# PIC18F16Q41 register map
Vendor: Microchip
Registers are 8-bit, read-write, reset 0x0 unless marked. A register's access mark holds for its fields unless they carry their own. Addresses are absolute, and some are shared; only a register's first bit layout is shown; [hi:lo] are bit positions; {n}, {i} and the like mark numbered series.

## wg_ecwg
0x3BC CWG1CLK
  [0] CS
0x3BD CWG1ISM
  [3:0] ISM
0x3BE CWG1DBR
  [5:0] DBR
0x3BF CWG1DBF
  [5:0] DBF
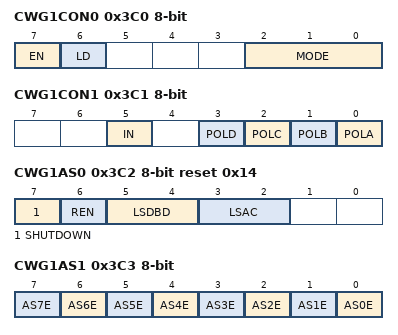
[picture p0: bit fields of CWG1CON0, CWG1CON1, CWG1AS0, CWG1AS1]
0x3C0 CWG1CON0
  [7] EN, [6] LD, [2:0] MODE
0x3C1 CWG1CON1 reset not defined — (power-on value --x-0000)
  [5] IN ro, [3] POLD, [2] POLC, [1] POLB, [0] POLA
0x3C2 CWG1AS0 reset 0x14
  [7] SHUTDOWN, [6] REN, [5:4] LSDBD, [3:2] LSAC
0x3C3 CWG1AS1
  [n] AS{n}E (n=0..7)
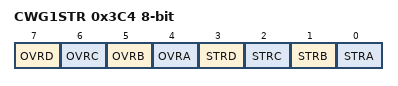
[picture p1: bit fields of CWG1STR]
0x3C4 CWG1STR
  [7] OVRD, [6] OVRC, [5] OVRB, [4] OVRA, [3] STRD, [2] STRC, [1] STRB, [0] STRA

## amp_fvr_ts_ctrl
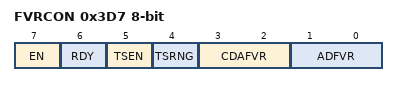
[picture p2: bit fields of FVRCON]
0x3D7 FVRCON reset not defined — (power-on value xx000000)
  [7] EN — Zero-Cross Detect Software Enable bit
  [6] RDY ro
  [5] TSEN — Zero-Cross Detect Data Output
  [4] TSRNG — Zero-Cross Detect Polarity bit
  [3:2] CDAFVR
  [1:0] ADFVR — Zero-Cross Detect Positive-going Edge Interrupt Enable

## adc_sarcore_mp_ctrl
0x3D9 ADLTHL
  [7:0] LTH
0x3DA ADLTHH
  [7:0] LTH
0x3DB ADUTHL
  [7:0] UTH
0x3DC ADUTHH
  [7:0] UTH
0x3DD ADERRL ro reset not defined — (power-on value xxxxxxxx)
  [7:0] ERR
0x3DE ADERRH ro reset not defined — (power-on value xxxxxxxx)
  [7:0] ERR
0x3DF ADSTPTL
  [7:0] STPT
0x3E0 ADSTPTH
  [7:0] STPT
0x3E1 ADFLTRL ro reset not defined — (power-on value xxxxxxxx)
  [7:0] FLTR
0x3E2 ADFLTRH ro reset not defined — (power-on value xxxxxxxx)
  [7:0] FLTR
0x3E3 ADACCL reset not defined — (power-on value xxxxxxxx)
  [7:0] ACC
0x3E4 ADACCH reset not defined — (power-on value xxxxxxxx)
  [7:0] ACC
0x3E5 ADACCU reset not defined — (power-on value xxxxxxxx)
  [7:0] ACC
0x3E6 ADCNT reset not defined — (power-on value xxxxxxxx)
  [7:0] CNT
0x3E7 ADRPT
  [7:0] RPT
0x3E8 ADPREVL ro reset not defined — (power-on value xxxxxxxx)
  [7:0] PREV
0x3E9 ADPREVH ro reset not defined — (power-on value xxxxxxxx)
  [7:0] PREV
0x3EA ADRESL
  [7:0] RES
0x3EB ADRESH
  [7:0] RES
0x3EC ADPCH
  [7:0] PCH
0x3EE ADACQL
  [7:0] ACQ
0x3EF ADACQH
  [4:0] ACQ
0x3F0 ADCAP
  [4:0] CAP
0x3F1 ADPREL
  [7:0] PRE
0x3F2 ADPREH
  [4:0] PRE
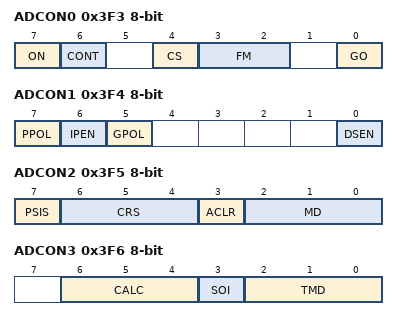
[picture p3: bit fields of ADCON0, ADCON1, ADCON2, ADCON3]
0x3F3 ADCON0
  [7] ON, [6] CONT, [4] CS, [3:2] FM, [0] GO
0x3F4 ADCON1
  [7] PPOL, [6] IPEN, [5] GPOL, [0] DSEN
0x3F5 ADCON2
  [7] PSIS, [6:4] CRS, [3] ACLR, [2:0] MD
0x3F6 ADCON3
  [6:4] CALC, [3] SOI, [2:0] TMD
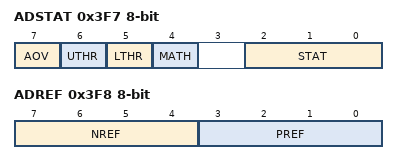
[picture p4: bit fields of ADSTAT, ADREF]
0x3F7 ADSTAT
  [7] AOV ro
  [6] UTHR ro
  [5] LTHR ro
  [4] MATH — (can only be cleared)
  [2:0] STAT ro
0x3F8 ADREF
  [7:4] NREF, [3:0] PREF
0x3F9 ADACT
  [4:0] ACT
0x3FA ADCLK
  [5:0] CS

## DOS_xxxxx_port_control
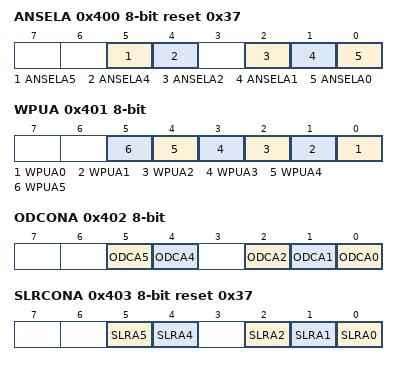
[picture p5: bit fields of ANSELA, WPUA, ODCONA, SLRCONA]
0x400 ANSELA reset 0x37
  [5] ANSELA5, [4] ANSELA4, [2] ANSELA2, [1] ANSELA1, [0] ANSELA0
0x401 WPUA
  [n] WPUA{n} (n=0..5)
0x402 ODCONA
  [5] ODCA5, [4] ODCA4, [2] ODCA2, [1] ODCA1, [0] ODCA0
0x403 SLRCONA reset 0x37
  [5] SLRA5, [4] SLRA4, [2] SLRA2, [1] SLRA1, [0] SLRA0
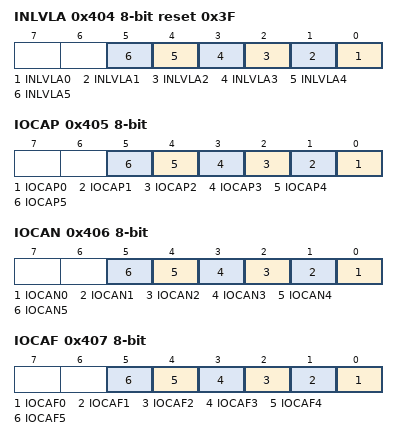
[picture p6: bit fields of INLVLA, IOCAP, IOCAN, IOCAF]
0x404 INLVLA reset 0x3F
  [n] INLVLA{n} (n=0..5)
0x405 IOCAP
  [n] IOCAP{n} (n=0..5)
0x406 IOCAN
  [n] IOCAN{n} (n=0..5)
0x407 IOCAF
  [n] IOCAF{n} (n=0..5)
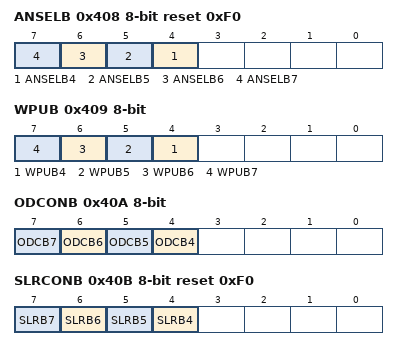
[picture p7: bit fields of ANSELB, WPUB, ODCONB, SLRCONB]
0x408 ANSELB reset 0xF0
  [n] ANSELB{n} (n=4..7)
0x409 WPUB
  [n] WPUB{n} (n=4..7)
0x40A ODCONB
  [n] ODCB{n} (n=4..7)
0x40B SLRCONB reset 0xF0
  [n] SLRB{n} (n=4..7)
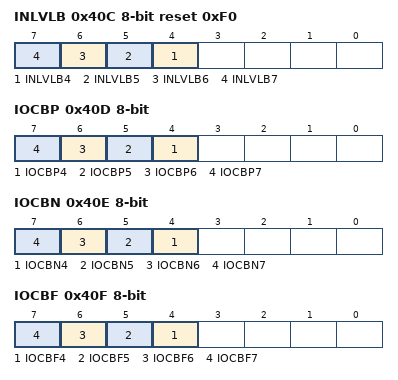
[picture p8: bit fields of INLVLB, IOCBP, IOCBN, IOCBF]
0x40C INLVLB reset 0xF0
  [n] INLVLB{n} (n=4..7)
0x40D IOCBP
  [n] IOCBP{n} (n=4..7)
0x40E IOCBN
  [n] IOCBN{n} (n=4..7)
0x40F IOCBF
  [n] IOCBF{n} (n=4..7)
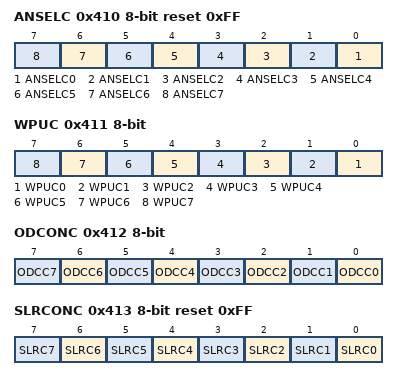
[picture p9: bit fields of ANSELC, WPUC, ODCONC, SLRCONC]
0x410 ANSELC reset 0xFF
  [n] ANSELC{n} (n=0..7)
0x411 WPUC
  [n] WPUC{n} (n=0..7)
0x412 ODCONC
  [n] ODCC{n} (n=0..7)
0x413 SLRCONC reset 0xFF
  [n] SLRC{n} (n=0..7)
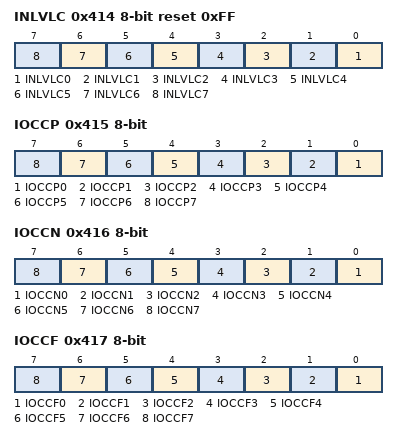
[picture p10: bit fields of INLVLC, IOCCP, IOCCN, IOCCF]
0x414 INLVLC reset 0xFF
  [n] INLVLC{n} (n=0..7)
0x415 IOCCP
  [n] IOCCP{n} (n=0..7)
0x416 IOCCN
  [n] IOCCN{n} (n=0..7)
0x417 IOCCF
  [n] IOCCF{n} (n=0..7)

## tmr_dds
0x440 NCO1ACCL
  [7:0] ACC
0x441 NCO1ACCH
  [7:0] ACC
0x442 NCO1ACCU
  [3:0] ACC
0x443 NCO1INCL reset 0x1
  [7:0] INC
0x444 NCO1INCH
  [7:0] INC
0x445 NCO1INCU
  [3:0] INC
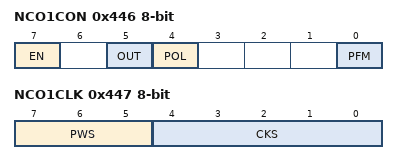
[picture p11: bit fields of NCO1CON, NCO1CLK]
0x446 NCO1CON — Configurable logic cell control
  [7] EN, [5] OUT ro, [4] POL, [0] PFM
0x447 NCO1CLK
  [7:5] PWS, [4:0] CKS

## int
0x459 IVTLOCK
  [0] IVTLOCKED
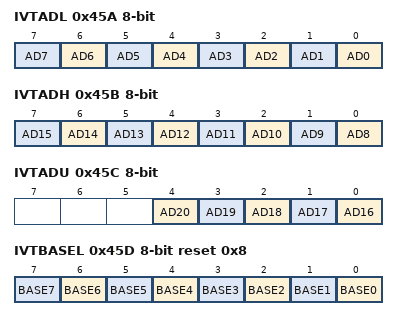
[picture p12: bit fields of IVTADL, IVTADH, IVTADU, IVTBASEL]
0x45A IVTADL
  [n] AD{n} (n=0..7)
0x45B IVTADH
  [n-8] AD{n} (n=8..15)
0x45C IVTADU
  [n-16] AD{n} (n=16..20)
0x45D IVTBASEL reset 0x8
  [n] BASE{n} (n=0..7)
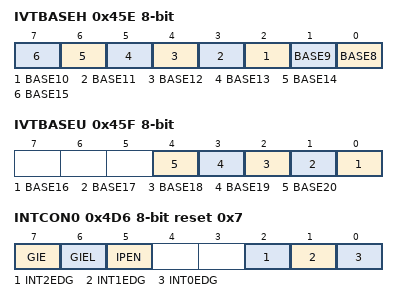
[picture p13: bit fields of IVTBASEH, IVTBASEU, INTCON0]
0x45E IVTBASEH
  [n-8] BASE{n} (n=8..15)
0x45F IVTBASEU
  [n-16] BASE{n} (n=16..20)
0x4D6 INTCON0 reset 0x7
  [7] GIE, [6] GIEL, [5] IPEN, [2] INT2EDG, [1] INT1EDG, [0] INT0EDG
0x4D7 INTCON1 ro
  [7:6] STAT

## pwm_cmp
{0x451+0xF*i} PWM{i}ERS (i=1..3)
  [7:0] ERS
{0x452+0xF*i} PWM{i}CLK (i=1..3)
  [7:0] CLK
{0x453+0xF*i} PWM{i}LDS (i=1..3)
  [7:0] LDS
{0x454+0xF*i} PWM{i}PRL (i=1..3)
  [7:0] PRL
{0x455+0xF*i} PWM{i}PRH (i=1..3)
  [7:0] PRH
{0x456+0xF*i} PWM{i}CPRE (i=1..3)
  [7:0] CPRE
{0x457+0xF*i} PWM{i}PIPOS (i=1..3)
  [7:0] PIPOS
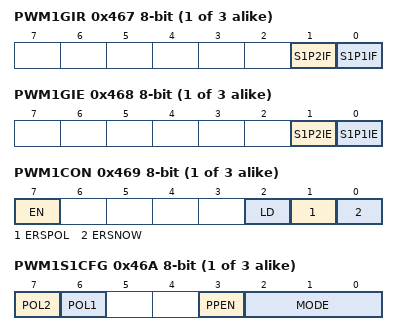
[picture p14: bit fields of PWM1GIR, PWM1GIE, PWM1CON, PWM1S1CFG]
{0x458+0xF*i} PWM{i}GIR (i=1..3)
  [1] S1P2IF, [0] S1P1IF
{0x459+0xF*i} PWM{i}GIE (i=1..3)
  [1] S1P2IE, [0] S1P1IE
{0x45A+0xF*i} PWM{i}CON (i=1..3)
  [7] EN, [2] LD, [1] ERSPOL, [0] ERSNOW
{0x45B+0xF*i} PWM{i}S1CFG (i=1..3)
  [7] POL2, [6] POL1, [3] PPEN, [2:0] MODE
{0x45C+0xF*i} PWM{i}S1P1L (i=1..3)
  [7:0] S1P1L
{0x45D+0xF*i} PWM{i}S1P1H (i=1..3)
  [7:0] S1P1H
{0x45E+0xF*i} PWM{i}S1P2L (i=1..3)
  [7:0] S1P2L
{0x45F+0xF*i} PWM{i}S1P2H (i=1..3)
  [7:0] S1P2H
